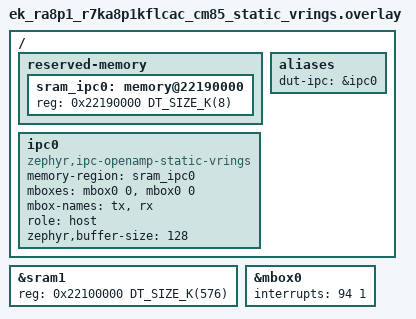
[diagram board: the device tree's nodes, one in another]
/*
 * Copyright (c) 2026 Renesas Electronics Corporation
 *
 * SPDX-License-Identifier: Apache-2.0
 */

#include <zephyr/dt-bindings/ipc_service/static_vrings.h>

/ {
	reserved-memory {
		#address-cells = <1>;
		#size-cells = <1>;

		sram_ipc0: memory@22190000 {
			reg = <0x22190000 DT_SIZE_K(8)>;
		};
	};

	ipc0: ipc0 {
		compatible = "zephyr,ipc-openamp-static-vrings";
		memory-region = <&sram_ipc0>;
		mboxes = <&mbox0 0>, <&mbox0 0>;
		mbox-names = "tx", "rx";
		role = "host";
		zephyr,buffer-size = <128>;
		status = "okay";
	};

	aliases {
		dut-ipc = &ipc0;
	};
};

/* Shrink CPU1 SRAM so it does not overlap the IPC shared region */
&sram1 {
	reg = <0x22100000 DT_SIZE_K(576)>;
};

&mbox0 {
	interrupts = <94 1>;
	status = "okay";
};
